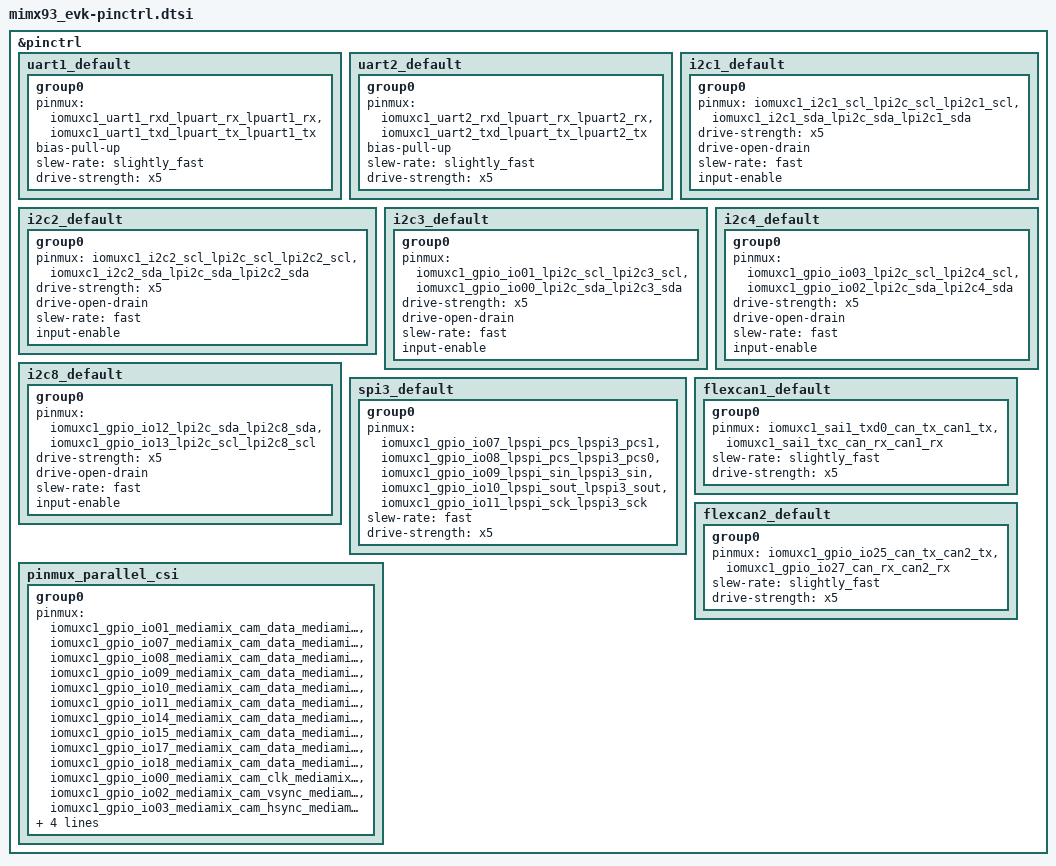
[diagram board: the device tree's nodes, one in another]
/*
 * Copyright (c) 2022, NXP
 * SPDX-License-Identifier: Apache-2.0
 *
 */

#include <nxp/nxp_imx/mimx9352cvuxk-pinctrl.dtsi>

&pinctrl {
	uart1_default: uart1_default {
		group0 {
			pinmux = <&iomuxc1_uart1_rxd_lpuart_rx_lpuart1_rx>,
			         <&iomuxc1_uart1_txd_lpuart_tx_lpuart1_tx>;
			bias-pull-up;
			slew-rate = "slightly_fast";
			drive-strength = "x5";
		};
	};

	uart2_default: uart2_default {
		group0 {
			pinmux = <&iomuxc1_uart2_rxd_lpuart_rx_lpuart2_rx>,
			         <&iomuxc1_uart2_txd_lpuart_tx_lpuart2_tx>;
			bias-pull-up;
			slew-rate = "slightly_fast";
			drive-strength = "x5";
		};
	};

	i2c1_default: i2c1_default {
		group0 {
			pinmux = <&iomuxc1_i2c1_scl_lpi2c_scl_lpi2c1_scl>,
			         <&iomuxc1_i2c1_sda_lpi2c_sda_lpi2c1_sda>;
			drive-strength = "x5";
			drive-open-drain;
			slew-rate = "fast";
			input-enable;
		};
	};

	i2c2_default: i2c2_default {
		group0 {
			pinmux = <&iomuxc1_i2c2_scl_lpi2c_scl_lpi2c2_scl>,
			         <&iomuxc1_i2c2_sda_lpi2c_sda_lpi2c2_sda>;
			drive-strength = "x5";
			drive-open-drain;
			slew-rate = "fast";
			input-enable;
		};
	};

	i2c3_default: i2c3_default {
		group0 {
			pinmux = <&iomuxc1_gpio_io01_lpi2c_scl_lpi2c3_scl>,
			         <&iomuxc1_gpio_io00_lpi2c_sda_lpi2c3_sda>;
			drive-strength = "x5";
			drive-open-drain;
			slew-rate = "fast";
			input-enable;
		};
	};

	i2c4_default: i2c4_default {
		group0 {
			pinmux = <&iomuxc1_gpio_io03_lpi2c_scl_lpi2c4_scl>,
			         <&iomuxc1_gpio_io02_lpi2c_sda_lpi2c4_sda>;
			drive-strength = "x5";
			drive-open-drain;
			slew-rate = "fast";
			input-enable;
		};
	};

	i2c8_default: i2c8_default {
		group0 {
			pinmux = <&iomuxc1_gpio_io12_lpi2c_sda_lpi2c8_sda>,
			         <&iomuxc1_gpio_io13_lpi2c_scl_lpi2c8_scl>;
			drive-strength = "x5";
			drive-open-drain;
			slew-rate = "fast";
			input-enable;
		};
	};

	spi3_default: spi3_default {
		group0 {
			pinmux = <&iomuxc1_gpio_io07_lpspi_pcs_lpspi3_pcs1>,
			         <&iomuxc1_gpio_io08_lpspi_pcs_lpspi3_pcs0>,
			         <&iomuxc1_gpio_io09_lpspi_sin_lpspi3_sin>,
			         <&iomuxc1_gpio_io10_lpspi_sout_lpspi3_sout>,
			         <&iomuxc1_gpio_io11_lpspi_sck_lpspi3_sck>;
			slew-rate = "fast";
			drive-strength = "x5";
		};
	};

	flexcan1_default: flexcan1_default {
		group0 {
			pinmux = <&iomuxc1_sai1_txd0_can_tx_can1_tx>,
			         <&iomuxc1_sai1_txc_can_rx_can1_rx>;
			slew-rate = "slightly_fast";
			drive-strength = "x5";
		};
	};

	flexcan2_default: flexcan2_default {
		group0 {
			pinmux = <&iomuxc1_gpio_io25_can_tx_can2_tx>,
			         <&iomuxc1_gpio_io27_can_rx_can2_rx>;
			slew-rate = "slightly_fast";
			drive-strength = "x5";
		};
	};

	pinmux_parallel_csi: pinmux_parallel_csi {
		group0 {
			pinmux = <&iomuxc1_gpio_io01_mediamix_cam_data_mediamix_cam_data00>,
				 <&iomuxc1_gpio_io07_mediamix_cam_data_mediamix_cam_data01>,
				 <&iomuxc1_gpio_io08_mediamix_cam_data_mediamix_cam_data02>,
				 <&iomuxc1_gpio_io09_mediamix_cam_data_mediamix_cam_data03>,
				 <&iomuxc1_gpio_io10_mediamix_cam_data_mediamix_cam_data04>,
				 <&iomuxc1_gpio_io11_mediamix_cam_data_mediamix_cam_data05>,
				 <&iomuxc1_gpio_io14_mediamix_cam_data_mediamix_cam_data06>,
				 <&iomuxc1_gpio_io15_mediamix_cam_data_mediamix_cam_data07>,
				 <&iomuxc1_gpio_io17_mediamix_cam_data_mediamix_cam_data08>,
				 <&iomuxc1_gpio_io18_mediamix_cam_data_mediamix_cam_data09>,
				 <&iomuxc1_gpio_io00_mediamix_cam_clk_mediamix_cam_clk>,
				 <&iomuxc1_gpio_io02_mediamix_cam_vsync_mediamix_cam_vsync>,
				 <&iomuxc1_gpio_io03_mediamix_cam_hsync_mediamix_cam_hsync>;
			drive-open-drain;
			bias-pull-up;
			slew-rate = "fast";
			drive-strength = "x4";
		};
	};

};
